AUTOSAR XML (schema 4-0-3)
package /ComponentTypes
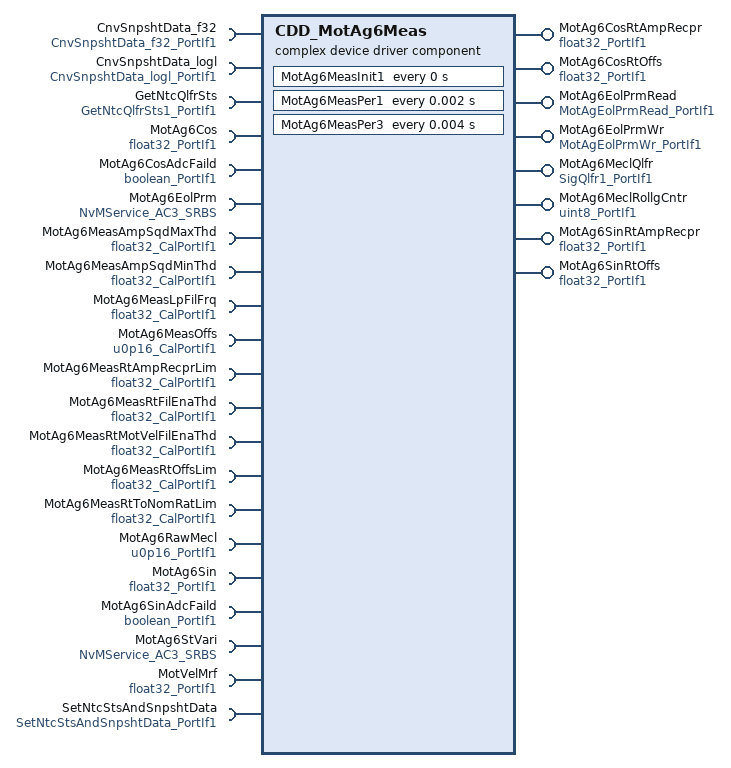
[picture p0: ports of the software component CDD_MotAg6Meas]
  complex device driver sw component type CDD_MotAg6Meas
    8 x provide port:
      MotAg6CosRtAmpRecpr: nonqueued-sender-com-spec{data-element=Val, init-value=1}, provided-interface=float32_PortIf1
      MotAg6CosRtOffs: nonqueued-sender-com-spec{data-element=Val, init-value=2.5}, provided-interface=float32_PortIf1
      MotAg6EolPrmRead: server-com-spec{operation=Oper, queue-length=1}, provided-interface=MotAgEolPrmRead_PortIf1
      MotAg6EolPrmWr: server-com-spec{operation=Oper, queue-length=1}, provided-interface=MotAgEolPrmWr_PortIf1
      MotAg6MeclQlfr: nonqueued-sender-com-spec{data-element=Val, init-value=0}, provided-interface=SigQlfr1_PortIf1
      MotAg6MeclRollgCntr: nonqueued-sender-com-spec{data-element=Val, init-value=0}, provided-interface=uint8_PortIf1
      MotAg6SinRtAmpRecpr: nonqueued-sender-com-spec{data-element=Val, init-value=1}, provided-interface=float32_PortIf1
      MotAg6SinRtOffs: nonqueued-sender-com-spec{data-element=Val, init-value=2.5}, provided-interface=float32_PortIf1
    21 x require port:
      CnvSnpshtData_f32: client-com-spec=Oper, required-interface=CnvSnpshtData_f32_PortIf1
      CnvSnpshtData_logl: client-com-spec=Oper, required-interface=CnvSnpshtData_logl_PortIf1
      GetNtcQlfrSts: client-com-spec=Oper, required-interface=GetNtcQlfrSts1_PortIf1
      MotAg6Cos: nonqueued-receiver-com-spec{data-element=Val, filter=data-filter-type=ALWAYS, init-value=1.65}, required-interface=float32_PortIf1
      MotAg6CosAdcFaild: nonqueued-receiver-com-spec{data-element=Logl, filter=data-filter-type=ALWAYS, init-value=0}, required-interface=boolean_PortIf1
      MotAg6EolPrm: required-com-specs=[EraseBlock, GetErrorStatus, InvalidateNvBlock, ReadBlock, SetRamBlockStatus, WriteBlock], required-interface=NvMService_AC3_SRBS
      MotAg6MeasAmpSqdMaxThd: parameter-require-com-spec{init-value=2.8, parameter=Val}, required-interface=float32_CalPortIf1
      MotAg6MeasAmpSqdMinThd: parameter-require-com-spec{init-value=0.0625, parameter=Val}, required-interface=float32_CalPortIf1
      MotAg6MeasLpFilFrq: parameter-require-com-spec{init-value=0.1, parameter=Val}, required-interface=float32_CalPortIf1
      MotAg6MeasOffs: parameter-require-com-spec{init-value=0, parameter=Val}, required-interface=u0p16_CalPortIf1
      MotAg6MeasRtAmpRecprLim: parameter-require-com-spec{init-value=0.122, parameter=Val}, required-interface=float32_CalPortIf1
      MotAg6MeasRtFilEnaThd: parameter-require-com-spec{init-value=0.99, parameter=Val}, required-interface=float32_CalPortIf1
      MotAg6MeasRtMotVelFilEnaThd: parameter-require-com-spec{init-value=100, parameter=Val}, required-interface=float32_CalPortIf1
      MotAg6MeasRtOffsLim: parameter-require-com-spec{init-value=0.1, parameter=Val}, required-interface=float32_CalPortIf1
      MotAg6MeasRtToNomRatLim: parameter-require-com-spec{init-value=0.1, parameter=Val}, required-interface=float32_CalPortIf1
      MotAg6RawMecl: nonqueued-receiver-com-spec{data-element=Val, filter=data-filter-type=ALWAYS, init-value=0}, required-interface=u0p16_PortIf1
      MotAg6Sin: nonqueued-receiver-com-spec{data-element=Val, filter=data-filter-type=ALWAYS, init-value=1.65}, required-interface=float32_PortIf1
      MotAg6SinAdcFaild: nonqueued-receiver-com-spec{data-element=Logl, filter=data-filter-type=ALWAYS, init-value=0}, required-interface=boolean_PortIf1
      MotAg6StVari: required-com-specs=[EraseBlock, GetErrorStatus, InvalidateNvBlock, ReadBlock, SetRamBlockStatus, WriteBlock], required-interface=NvMService_AC3_SRBS
      MotVelMrf: nonqueued-receiver-com-spec{data-element=Val, filter=data-filter-type=ALWAYS, init-value=0}, required-interface=float32_PortIf1
      SetNtcStsAndSnpshtData: client-com-spec=Oper, required-interface=SetNtcStsAndSnpshtData_PortIf1
    behavior CDD_MotAg6Meas_InternalBehavior
      ar-typed-per-instance-memorys:
        11 x data, all with sw-calibration-access=READ-ONLY:
          dMotAg6MeasAmpVal: type=float32
          MotAg6CosMaxLpFil: type=FilLpRec1
          MotAg6CosMinLpFil: type=FilLpRec1
          MotAg6EolPrm: type=MotAgEolPrmRec1
          MotAg6NvmFltEna: type=boolean
          MotAg6PrevRollgCntr: type=uint8
          MotAg6RtPrm: type=MotAgRtPrmRec1
          MotAg6SinMaxLpFil: type=FilLpRec1
          MotAg6SinMinLpFil: type=FilLpRec1
          MotAg6StVari: type=MotAgStVariRec1
          PrevMotAg6Mecl: type=u0p16
      operation invoked event OIT_MotAg6EolPrmRead_Oper_MotAg6EolPrmRead_Oper: start-on-event=MotAg6EolPrmRead_Oper, operation=MotAg6EolPrmRead.Oper
      operation invoked event OIT_MotAg6EolPrmWr_Oper_MotAg6EolPrmWr_Oper: start-on-event=MotAg6EolPrmWr_Oper, operation=MotAg6EolPrmWr.Oper
      timing event MotAg6Meas_InitEvent: start-on-event=MotAg6MeasInit1, period=0
      timing event TMT_MotAg6MeasPer1: start-on-event=MotAg6MeasPer1, period=0.002
      timing event TMT_MotAg6MeasPer3: start-on-event=MotAg6MeasPer3, period=0.004
      explicit-inter-runnable-variables:
        data MotAg6PrtclOk: type=boolean, init-value=0
        data MotAg6RtVari: type=MotAgRtPrmRec1, init-value=fields=[SinRtOffs:2.5, SinRtAmpRecpr:1, CosRtOffs:2.5, CosRtAmpRecpr:1, SinGainCorrd:1, CosGainCorrd:1, SinOffsCorrd:0, CosOffsCorrd:0, CosSinNomRatio:1, SinCosNomRatio:1, RtToNomRatioLoLim:1, RtToNomRatioHiLim:1, PrevSinRtOffs:2.5, PrevCosRtOffs:2.5]
      5 x runnable:
        MotAg6EolPrmRead_Oper
        MotAg6EolPrmWr_Oper
          sync call SC_MotAg6EolPrm_SetRamBlockStatus: operation=MotAg6EolPrm.SetRamBlockStatus, timeout=0
        MotAg6MeasInit1
          sync call SC_MotAg6EolPrm_GetErrorStatus: operation=MotAg6EolPrm.GetErrorStatus, timeout=0
          sync call SC_MotAg6StVari_GetErrorStatus: operation=MotAg6StVari.GetErrorStatus, timeout=0
        MotAg6MeasPer1
          data-receive-point-by-arguments:
            4 x access:
              REC_MotAg6Cos_Val: accessed-variable=MotAg6Cos.Val
              REC_MotAg6CosAdcFaild_Logl: accessed-variable=MotAg6CosAdcFaild.Logl
              REC_MotAg6Sin_Val: accessed-variable=MotAg6Sin.Val
              REC_MotAg6SinAdcFaild_Logl: accessed-variable=MotAg6SinAdcFaild.Logl
          data-send-points:
            6 x access:
              SEND_MotAg6CosRtAmpRecpr_Val: accessed-variable=MotAg6CosRtAmpRecpr.Val
              SEND_MotAg6CosRtOffs_Val: accessed-variable=MotAg6CosRtOffs.Val
              SEND_MotAg6Qlfr_Val: accessed-variable=MotAg6MeclQlfr.Val
              SEND_MotAg6RollgCntr_Val: accessed-variable=MotAg6MeclRollgCntr.Val
              SEND_MotAg6SinRtAmpRecpr_Val: accessed-variable=MotAg6SinRtAmpRecpr.Val
              SEND_MotAg6SinRtOffs_Val: accessed-variable=MotAg6SinRtOffs.Val
          read-local-variables:
            access READ_MotAg6RtVari: accessed-variable=MotAg6RtVari
          4 x sync call, all with timeout=0:
            SC_CnvSnpshtData_f32_Oper: operation=CnvSnpshtData_f32.Oper
            SC_CnvSnpshtData_logl_Oper: operation=CnvSnpshtData_logl.Oper
            SC_GetNtcQlfrSts1_Oper: operation=GetNtcQlfrSts.Oper
            SC_SetNtcStsAndSnpshtData_Oper: operation=SetNtcStsAndSnpshtData.Oper
          written-local-variables:
            access WRITE_MotAg6PrtclOk: accessed-variable=MotAg6PrtclOk
        MotAg6MeasPer3
          data-receive-point-by-arguments:
            4 x access:
              REC_MotAg6Cos_Val: accessed-variable=MotAg6Cos.Val
              REC_MotAg6RawMecl_Val: accessed-variable=MotAg6RawMecl.Val
              REC_MotAg6Sin_Val: accessed-variable=MotAg6Sin.Val
              REC_MotVelMrf_Val: accessed-variable=MotVelMrf.Val
          read-local-variables:
            access READ_MotAg6PrtclOk: accessed-variable=MotAg6PrtclOk
          sync call SC_MotAg6StVari_SetRamBlockStatus: operation=MotAg6StVari.SetRamBlockStatus, timeout=0
          written-local-variables:
            access WRITE_MotAg6RtVari: accessed-variable=MotAg6RtVari
      swc service dependency MotAg6EolPrmNvm: assigned-datas=role-based-data-assignment={role=ramBlock, used-data-element=MotAg6EolPrm}, assigned-ports=role-based-port-assignment={port-prototype=MotAg6EolPrm, role=NvMService_AC3_SRBS}
        service-needs:
          nv block needs MotAg6EolPrmNvm: n-data-sets=0, readonly=false, reliability=ERROR-DETECTION, resistant-to-changed-sw=true, restore-at-start=true, store-at-shutdown=true
      swc service dependency MotAg6StVariNvm: assigned-datas=role-based-data-assignment={role=ramBlock, used-data-element=MotAg6StVari}, assigned-ports=role-based-port-assignment={port-prototype=MotAg6StVari, role=NvMService_AC3_SRBS}
        service-needs:
          nv block needs MotAg6StVariNvm: n-data-sets=0, readonly=false, reliability=ERROR-DETECTION, resistant-to-changed-sw=true, restore-at-start=true, store-at-shutdown=true
  swc implementation CDD_MotAg6Meas_Implementation: behavior=CDD_MotAg6Meas_InternalBehavior
    code-descriptors:
      code Default: artifact-descriptors=autosar-engineering-object={short-label=Default, category=SWSRC}
